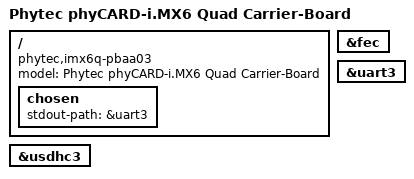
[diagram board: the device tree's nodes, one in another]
/*
 * Copyright 2014 Christian Hemp, Phytec Messtechnik GmbH
 *
 * The code contained herein is licensed under the GNU General Public
 * License. You may obtain a copy of the GNU General Public License
 * Version 2 or later at the following locations:
 *
 * http://www.opensource.org/licenses/gpl-license.html
 * http://www.gnu.org/copyleft/gpl.html
 */

/dts-v1/;
#include "imx6q-phytec-pcaaxl3.dtsi"

/ {
	model = "Phytec phyCARD-i.MX6 Quad Carrier-Board";
	compatible = "phytec,imx6q-pbaa03", "phytec,imx6q-pcaaxl3", "fsl,imx6q";

	chosen {
		stdout-path = &uart3;
	};
};

&fec {
	status = "okay";
};

&uart3 {
	status = "okay";
};

&usdhc3 {
	status = "okay";
};
